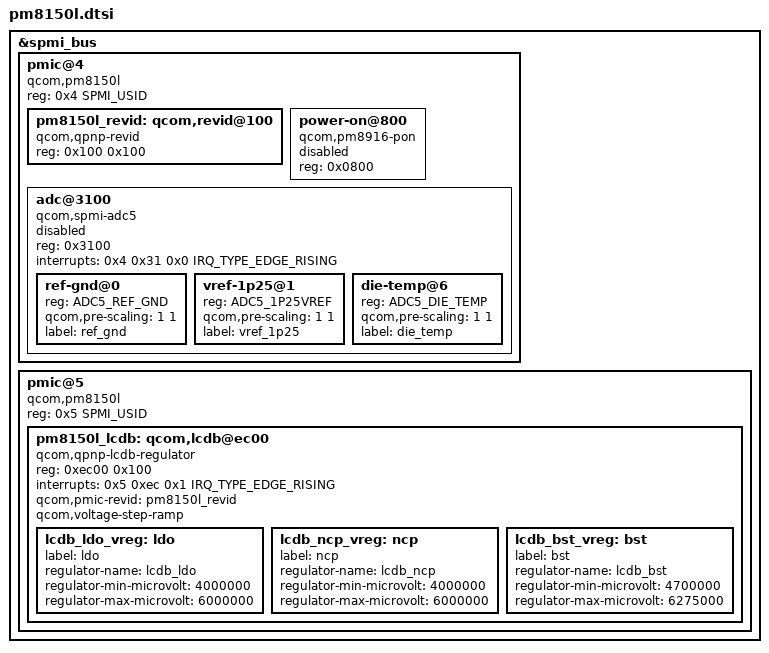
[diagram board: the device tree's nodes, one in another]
// SPDX-License-Identifier: BSD-3-Clause
/*
 * Copyright (c) 2017-2019, The Linux Foundation. All rights reserved.
 * Copyright (c) 2019, Linaro Limited
 */

#include <dt-bindings/iio/qcom,spmi-vadc.h>
#include <dt-bindings/interrupt-controller/irq.h>
#include <dt-bindings/spmi/spmi.h>

&spmi_bus {
	pmic@4 {
		compatible = "qcom,pm8150l", "qcom,spmi-pmic";
		reg = <0x4 SPMI_USID>;
		#address-cells = <1>;
		#size-cells = <0>;

		pm8150l_revid: qcom,revid@100 {
			compatible = "qcom,qpnp-revid";
			reg = <0x100 0x100>;
		};


		power-on@800 {
			compatible = "qcom,pm8916-pon";
			reg = <0x0800>;

			status = "disabled";
		};

		adc@3100 {
			compatible = "qcom,spmi-adc5";
			reg = <0x3100>;
			#address-cells = <1>;
			#size-cells = <0>;
			#io-channel-cells = <1>;
			interrupts = <0x4 0x31 0x0 IRQ_TYPE_EDGE_RISING>;

			status = "disabled";

			ref-gnd@0 {
				reg = <ADC5_REF_GND>;
				qcom,pre-scaling = <1 1>;
				label = "ref_gnd";
			};

			vref-1p25@1 {
				reg = <ADC5_1P25VREF>;
				qcom,pre-scaling = <1 1>;
				label = "vref_1p25";
			};

			die-temp@6 {
				reg = <ADC5_DIE_TEMP>;
				qcom,pre-scaling = <1 1>;
				label = "die_temp";
			};
		};

#if 0
		pm8150l_gpios: gpio@c000 {
			compatible = "qcom,pm8150l-gpio";
			reg = <0xc000>;
			gpio-controller;
			#gpio-cells = <2>;
			interrupt-controller;
			#interrupt-cells = <2>;
		};
#endif
	};

	pmic@5 {
		compatible = "qcom,pm8150l", "qcom,spmi-pmic";
		reg = <0x5 SPMI_USID>;
		#address-cells = <1>;
		#size-cells = <0>;

		pm8150l_lcdb: qcom,lcdb@ec00 {
			compatible = "qcom,qpnp-lcdb-regulator";
			reg = <0xec00 0x100>;
			interrupts = <0x5 0xec 0x1 IRQ_TYPE_EDGE_RISING>;
			interrupt-names = "sc-irq";
			qcom,pmic-revid = <&pm8150l_revid>;
			qcom,voltage-step-ramp;

			lcdb_ldo_vreg: ldo {
				label = "ldo";
				regulator-name = "lcdb_ldo";
				regulator-min-microvolt = <4000000>;
				regulator-max-microvolt = <6000000>;
			};

			lcdb_ncp_vreg: ncp {
				label = "ncp";
				regulator-name = "lcdb_ncp";
				regulator-min-microvolt = <4000000>;
				regulator-max-microvolt = <6000000>;
			};

			lcdb_bst_vreg: bst {
				label = "bst";
				regulator-name = "lcdb_bst";
				regulator-min-microvolt = <4700000>;
				regulator-max-microvolt = <6275000>;
			};
		};
	};
};
